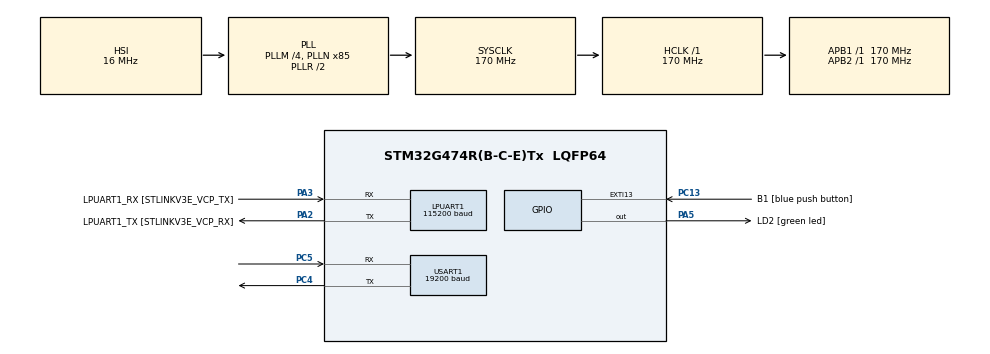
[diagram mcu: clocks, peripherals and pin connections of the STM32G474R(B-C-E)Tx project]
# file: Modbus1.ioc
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Dma.LPUART1_RX.2.Direction=DMA_PERIPH_TO_MEMORY
Dma.LPUART1_RX.2.EventEnable=DISABLE
Dma.LPUART1_RX.2.Instance=DMA1_Channel2
Dma.LPUART1_RX.2.MemDataAlignment=DMA_MDATAALIGN_BYTE
Dma.LPUART1_RX.2.MemInc=DMA_MINC_ENABLE
Dma.LPUART1_RX.2.Mode=DMA_NORMAL
Dma.LPUART1_RX.2.PeriphDataAlignment=DMA_PDATAALIGN_BYTE
Dma.LPUART1_RX.2.PeriphInc=DMA_PINC_DISABLE
Dma.LPUART1_RX.2.Polarity=HAL_DMAMUX_REQ_GEN_RISING
Dma.LPUART1_RX.2.Priority=DMA_PRIORITY_LOW
Dma.LPUART1_RX.2.RequestNumber=1
Dma.LPUART1_RX.2.SignalID=NONE
Dma.LPUART1_RX.2.SyncEnable=DISABLE
Dma.LPUART1_RX.2.SyncPolarity=HAL_DMAMUX_SYNC_NO_EVENT
Dma.LPUART1_RX.2.SyncRequestNumber=1
Dma.LPUART1_RX.2.SyncSignalID=NONE
Dma.LPUART1_TX.3.Direction=DMA_MEMORY_TO_PERIPH
Dma.LPUART1_TX.3.EventEnable=DISABLE
Dma.LPUART1_TX.3.Instance=DMA1_Channel1
Dma.LPUART1_TX.3.MemDataAlignment=DMA_MDATAALIGN_BYTE
Dma.LPUART1_TX.3.MemInc=DMA_MINC_ENABLE
Dma.LPUART1_TX.3.Mode=DMA_NORMAL
Dma.LPUART1_TX.3.PeriphDataAlignment=DMA_PDATAALIGN_BYTE
Dma.LPUART1_TX.3.PeriphInc=DMA_PINC_DISABLE
Dma.LPUART1_TX.3.Polarity=HAL_DMAMUX_REQ_GEN_RISING
Dma.LPUART1_TX.3.Priority=DMA_PRIORITY_LOW
Dma.LPUART1_TX.3.RequestNumber=1
Dma.LPUART1_TX.3.SignalID=NONE
Dma.LPUART1_TX.3.SyncEnable=DISABLE
Dma.LPUART1_TX.3.SyncPolarity=HAL_DMAMUX_SYNC_NO_EVENT
Dma.LPUART1_TX.3.SyncRequestNumber=1
Dma.LPUART1_TX.3.SyncSignalID=NONE
Dma.Request0=USART1_RX
Dma.Request1=USART1_TX
Dma.Request2=LPUART1_RX
Dma.Request3=LPUART1_TX
Dma.USART1_RX.0.Direction=DMA_PERIPH_TO_MEMORY
Dma.USART1_RX.0.EventEnable=DISABLE
Dma.USART1_RX.0.Instance=DMA1_Channel3
Dma.USART1_RX.0.MemDataAlignment=DMA_MDATAALIGN_BYTE
Dma.USART1_RX.0.MemInc=DMA_MINC_ENABLE
Dma.USART1_RX.0.Mode=DMA_NORMAL
Dma.USART1_RX.0.PeriphDataAlignment=DMA_PDATAALIGN_BYTE
Dma.USART1_RX.0.PeriphInc=DMA_PINC_DISABLE
Dma.USART1_RX.0.Polarity=HAL_DMAMUX_REQ_GEN_RISING
Dma.USART1_RX.0.Priority=DMA_PRIORITY_LOW
Dma.USART1_RX.0.RequestNumber=1
Dma.USART1_RX.0.SignalID=NONE
Dma.USART1_RX.0.SyncEnable=DISABLE
Dma.USART1_RX.0.SyncPolarity=HAL_DMAMUX_SYNC_NO_EVENT
Dma.USART1_RX.0.SyncRequestNumber=1
Dma.USART1_RX.0.SyncSignalID=NONE
Dma.USART1_TX.1.Direction=DMA_MEMORY_TO_PERIPH
Dma.USART1_TX.1.EventEnable=DISABLE
Dma.USART1_TX.1.Instance=DMA2_Channel1
Dma.USART1_TX.1.MemDataAlignment=DMA_MDATAALIGN_BYTE
Dma.USART1_TX.1.MemInc=DMA_MINC_ENABLE
Dma.USART1_TX.1.Mode=DMA_NORMAL
Dma.USART1_TX.1.PeriphDataAlignment=DMA_PDATAALIGN_BYTE
Dma.USART1_TX.1.PeriphInc=DMA_PINC_DISABLE
Dma.USART1_TX.1.Polarity=HAL_DMAMUX_REQ_GEN_RISING
Dma.USART1_TX.1.Priority=DMA_PRIORITY_LOW
Dma.USART1_TX.1.RequestNumber=1
Dma.USART1_TX.1.SignalID=NONE
Dma.USART1_TX.1.SyncEnable=DISABLE
Dma.USART1_TX.1.SyncPolarity=HAL_DMAMUX_SYNC_NO_EVENT
Dma.USART1_TX.1.SyncRequestNumber=1
Dma.USART1_TX.1.SyncSignalID=NONE
LPUART1.BaudRate=115200
LPUART1.Parity=UART_PARITY_EVEN
LPUART1.WordLength=UART_WORDLENGTH_9B
Mcu.Family=STM32G4
Mcu.Name=STM32G474R(B-C-E)Tx
Mcu.Package=LQFP64
NVIC.DMA1_Channel1_IRQn=true\:0\:0\:false\:false\:true\:false\:true\:true
NVIC.DMA1_Channel2_IRQn=true\:0\:0\:false\:false\:true\:false\:true\:true
NVIC.DMA1_Channel3_IRQn=true\:0\:0\:false\:false\:true\:false\:true\:true
NVIC.DMA2_Channel1_IRQn=true\:0\:0\:false\:false\:true\:false\:true\:true
NVIC.EXTI15_10_IRQn=true\:0\:0\:false\:false\:true\:true\:true\:true
NVIC.LPUART1_IRQn=true\:0\:0\:false\:false\:true\:true\:true\:true
NVIC.PriorityGroup=NVIC_PRIORITYGROUP_4
NVIC.TIM1_UP_TIM16_IRQn=true\:0\:0\:false\:false\:true\:true\:true\:true
NVIC.USART1_IRQn=true\:0\:0\:false\:false\:true\:true\:true\:true
PA13.GPIO_Label=T_SWDIO
PA13.Mode=Serial_Wire
PA13.Signal=SYS_JTMS-SWDIO
PA14.GPIO_Label=T_SWCLK
PA14.Mode=Serial_Wire
PA14.Signal=SYS_JTCK-SWCLK
PA2.GPIO_Label=LPUART1_TX [STLINKV3E_VCP_RX]
PA2.Mode=Asynchronous
PA2.Signal=LPUART1_TX
PA3.GPIO_Label=LPUART1_RX [STLINKV3E_VCP_TX]
PA3.Mode=Asynchronous
PA3.Signal=LPUART1_RX
PA5.GPIO_Label=LD2 [green led]
PA5.Signal=GPIO_Output
PB3.GPIO_Label=T_SWO
PB3.Signal=SYS_JTDO-SWO
PC13.GPIO_Label=B1 [blue push button]
PC13.Signal=GPXTI13
PC14-OSC32_IN.Mode=LSE-External-Oscillator
PC14-OSC32_IN.Signal=RCC_OSC32_IN
PC15-OSC32_OUT.Mode=LSE-External-Oscillator
PC15-OSC32_OUT.Signal=RCC_OSC32_OUT
PC4.Mode=Asynchronous
PC4.Signal=USART1_TX
PC5.Mode=Asynchronous
PC5.Signal=USART1_RX
PF0-OSC_IN.Mode=HSE-External-Oscillator
PF0-OSC_IN.Signal=RCC_OSC_IN
PF1-OSC_OUT.Mode=HSE-External-Oscillator
PF1-OSC_OUT.Signal=RCC_OSC_OUT
ProjectManager.HeapSize=0x200
ProjectManager.StackSize=0x400
ProjectManager.TargetToolchain=STM32CubeIDE
RCC.ADC12Freq_Value=170000000
RCC.ADC345Freq_Value=170000000
RCC.AHBFreq_Value=170000000
RCC.APB1Freq_Value=170000000
RCC.APB1TimFreq_Value=170000000
RCC.APB2Freq_Value=170000000
RCC.APB2TimFreq_Value=170000000
RCC.CortexFreq_Value=170000000
RCC.EXTERNAL_CLOCK_VALUE=12288000
RCC.HCLKFreq_Value=170000000
RCC.HSE_VALUE=24000000
RCC.HSI48_VALUE=48000000
RCC.HSI_VALUE=16000000
RCC.PLLM=RCC_PLLM_DIV4
RCC.PLLN=85
RCC.RTCClockSelection=RCC_RTCCLKSOURCE_LSE
RCC.SYSCLKFreq_VALUE=170000000
RCC.SYSCLKSource=RCC_SYSCLKSOURCE_PLLCLK
RCC.USBFreq_Value=170000000
RCC.VCOOutputFreq_Value=340000000
TIM16.PeriodNoDither=1145
TIM16.Prescaler=169
USART1.BaudRate=19200
USART1.Parity=PARITY_EVEN
USART1.VirtualMode-Asynchronous=VM_ASYNC
USART1.WordLength=WORDLENGTH_9B
VP_SYS_VS_DBSignals.Mode=DisableDeadBatterySignals
VP_TIM16_VS_ClockSourceINT.Mode=Enable_Timer
VP_TIM16_VS_OPM.Mode=OPM_bit
board=NUCLEO-G474RE

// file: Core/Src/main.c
/* USER CODE BEGIN Header */
/**
  ******************************************************************************
  * @file           : main.c
  * @brief          : Main program body
  ******************************************************************************
  * @attention
  *
  * Copyright (c) 2024 STMicroelectronics.
  * All rights reserved.
  *
  * This software is licensed under terms that can be found in the LICENSE file
  * in the root directory of this software component.
  * If no LICENSE file comes with this software, it is provided AS-IS.
  *
  ******************************************************************************
  */
/* USER CODE END Header */
#include "main.h"

/* USER CODE BEGIN Includes */
#include "ModBusRTU.h"
/* USER CODE END Includes */

UART_HandleTypeDef hlpuart1;
UART_HandleTypeDef huart1;
DMA_HandleTypeDef hdma_lpuart1_rx;
DMA_HandleTypeDef hdma_lpuart1_tx;
DMA_HandleTypeDef hdma_usart1_rx;
DMA_HandleTypeDef hdma_usart1_tx;

TIM_HandleTypeDef htim16;

/* USER CODE BEGIN PV */
ModbusHandleTypedef hmodbus;
u16u8_t registerFrame[200];
/* USER CODE END PV */

void SystemClock_Config(void);
static void MX_GPIO_Init(void);
static void MX_DMA_Init(void);
static void MX_LPUART1_UART_Init(void);
static void MX_USART1_UART_Init(void);
static void MX_TIM16_Init(void);

int main(void)
{

  /* MCU Configuration--------------------------------------------------------*/

  /* Reset of all peripherals, Initializes the Flash interface and the Systick. */
  HAL_Init();

  /* Configure the system clock */
  SystemClock_Config();

  /* Initialize all configured peripherals */
  MX_GPIO_Init();
  MX_DMA_Init();
  MX_LPUART1_UART_Init();
  MX_USART1_UART_Init();
  MX_TIM16_Init();
  /* USER CODE BEGIN 2 */
  hmodbus.huart = &hlpuart1;
  hmodbus.htim = &htim16;
  hmodbus.slaveAddress = 0x15;
  hmodbus.RegisterSize =200;
  Modbus_init(&hmodbus, registerFrame);
  /* USER CODE END 2 */

  /* Infinite loop */
  while (1)
  {

    /* USER CODE BEGIN 3 */
	  Modbus_Protocal_Worker();
  }
  /* USER CODE END 3 */
}

void SystemClock_Config(void)
{
  RCC_OscInitTypeDef RCC_OscInitStruct = {0};
  RCC_ClkInitTypeDef RCC_ClkInitStruct = {0};

  /** Configure the main internal regulator output voltage
  */
  HAL_PWREx_ControlVoltageScaling(PWR_REGULATOR_VOLTAGE_SCALE1_BOOST);

  /** Initializes the RCC Oscillators according to the specified parameters
  * in the RCC_OscInitTypeDef structure.
  */
  RCC_OscInitStruct.OscillatorType = RCC_OSCILLATORTYPE_HSI;
  RCC_OscInitStruct.HSIState = RCC_HSI_ON;
  RCC_OscInitStruct.HSICalibrationValue = RCC_HSICALIBRATION_DEFAULT;
  RCC_OscInitStruct.PLL.PLLState = RCC_PLL_ON;
  RCC_OscInitStruct.PLL.PLLSource = RCC_PLLSOURCE_HSI;
  RCC_OscInitStruct.PLL.PLLM = RCC_PLLM_DIV4;
  RCC_OscInitStruct.PLL.PLLN = 85;
  RCC_OscInitStruct.PLL.PLLP = RCC_PLLP_DIV2;
  RCC_OscInitStruct.PLL.PLLQ = RCC_PLLQ_DIV2;
  RCC_OscInitStruct.PLL.PLLR = RCC_PLLR_DIV2;
  if (HAL_RCC_OscConfig(&RCC_OscInitStruct) != HAL_OK)
  {
    Error_Handler();
  }

  /** Initializes the CPU, AHB and APB buses clocks
  */
  RCC_ClkInitStruct.ClockType = RCC_CLOCKTYPE_HCLK|RCC_CLOCKTYPE_SYSCLK
                              |RCC_CLOCKTYPE_PCLK1|RCC_CLOCKTYPE_PCLK2;
  RCC_ClkInitStruct.SYSCLKSource = RCC_SYSCLKSOURCE_PLLCLK;
  RCC_ClkInitStruct.AHBCLKDivider = RCC_SYSCLK_DIV1;
  RCC_ClkInitStruct.APB1CLKDivider = RCC_HCLK_DIV1;
  RCC_ClkInitStruct.APB2CLKDivider = RCC_HCLK_DIV1;

  if (HAL_RCC_ClockConfig(&RCC_ClkInitStruct, FLASH_LATENCY_4) != HAL_OK)
  {
    Error_Handler();
  }
}

static void MX_LPUART1_UART_Init(void)
{

  hlpuart1.Instance = LPUART1;
  hlpuart1.Init.BaudRate = 115200;
  hlpuart1.Init.WordLength = UART_WORDLENGTH_9B;
  hlpuart1.Init.StopBits = UART_STOPBITS_1;
  hlpuart1.Init.Parity = UART_PARITY_EVEN;
  hlpuart1.Init.Mode = UART_MODE_TX_RX;
  hlpuart1.Init.HwFlowCtl = UART_HWCONTROL_NONE;
  hlpuart1.Init.OneBitSampling = UART_ONE_BIT_SAMPLE_DISABLE;
  hlpuart1.Init.ClockPrescaler = UART_PRESCALER_DIV1;
  hlpuart1.AdvancedInit.AdvFeatureInit = UART_ADVFEATURE_NO_INIT;
  if (HAL_UART_Init(&hlpuart1) != HAL_OK)
  {
    Error_Handler();
  }
  if (HAL_UARTEx_SetTxFifoThreshold(&hlpuart1, UART_TXFIFO_THRESHOLD_1_8) != HAL_OK)
  {
    Error_Handler();
  }
  if (HAL_UARTEx_SetRxFifoThreshold(&hlpuart1, UART_RXFIFO_THRESHOLD_1_8) != HAL_OK)
  {
    Error_Handler();
  }
  if (HAL_UARTEx_DisableFifoMode(&hlpuart1) != HAL_OK)
  {
    Error_Handler();
  }

}

static void MX_USART1_UART_Init(void)
{

  huart1.Instance = USART1;
  huart1.Init.BaudRate = 19200;
  huart1.Init.WordLength = UART_WORDLENGTH_9B;
  huart1.Init.StopBits = UART_STOPBITS_1;
  huart1.Init.Parity = UART_PARITY_EVEN;
  huart1.Init.Mode = UART_MODE_TX_RX;
  huart1.Init.HwFlowCtl = UART_HWCONTROL_NONE;
  huart1.Init.OverSampling = UART_OVERSAMPLING_16;
  huart1.Init.OneBitSampling = UART_ONE_BIT_SAMPLE_DISABLE;
  huart1.Init.ClockPrescaler = UART_PRESCALER_DIV1;
  huart1.AdvancedInit.AdvFeatureInit = UART_ADVFEATURE_NO_INIT;
  if (HAL_UART_Init(&huart1) != HAL_OK)
  {
    Error_Handler();
  }
  if (HAL_UARTEx_SetTxFifoThreshold(&huart1, UART_TXFIFO_THRESHOLD_1_8) != HAL_OK)
  {
    Error_Handler();
  }
  if (HAL_UARTEx_SetRxFifoThreshold(&huart1, UART_RXFIFO_THRESHOLD_1_8) != HAL_OK)
  {
    Error_Handler();
  }
  if (HAL_UARTEx_DisableFifoMode(&huart1) != HAL_OK)
  {
    Error_Handler();
  }

}

static void MX_TIM16_Init(void)
{

  htim16.Instance = TIM16;
  htim16.Init.Prescaler = 169;
  htim16.Init.CounterMode = TIM_COUNTERMODE_UP;
  htim16.Init.Period = 1145;
  htim16.Init.ClockDivision = TIM_CLOCKDIVISION_DIV1;
  htim16.Init.RepetitionCounter = 0;
  htim16.Init.AutoReloadPreload = TIM_AUTORELOAD_PRELOAD_DISABLE;
  if (HAL_TIM_Base_Init(&htim16) != HAL_OK)
  {
    Error_Handler();
  }
  if (HAL_TIM_OnePulse_Init(&htim16, TIM_OPMODE_SINGLE) != HAL_OK)
  {
    Error_Handler();
  }

}

static void MX_DMA_Init(void)
{

  /* DMA controller clock enable */
  __HAL_RCC_DMAMUX1_CLK_ENABLE();
  __HAL_RCC_DMA1_CLK_ENABLE();
  __HAL_RCC_DMA2_CLK_ENABLE();

  /* DMA interrupt init */
  /* DMA1_Channel1_IRQn interrupt configuration */
  HAL_NVIC_SetPriority(DMA1_Channel1_IRQn, 0, 0);
  HAL_NVIC_EnableIRQ(DMA1_Channel1_IRQn);
  /* DMA1_Channel2_IRQn interrupt configuration */
  HAL_NVIC_SetPriority(DMA1_Channel2_IRQn, 0, 0);
  HAL_NVIC_EnableIRQ(DMA1_Channel2_IRQn);
  /* DMA1_Channel3_IRQn interrupt configuration */
  HAL_NVIC_SetPriority(DMA1_Channel3_IRQn, 0, 0);
  HAL_NVIC_EnableIRQ(DMA1_Channel3_IRQn);
  /* DMA2_Channel1_IRQn interrupt configuration */
  HAL_NVIC_SetPriority(DMA2_Channel1_IRQn, 0, 0);
  HAL_NVIC_EnableIRQ(DMA2_Channel1_IRQn);

}

static void MX_GPIO_Init(void)
{
  GPIO_InitTypeDef GPIO_InitStruct = {0};

  /* GPIO Ports Clock Enable */
  __HAL_RCC_GPIOC_CLK_ENABLE();
  __HAL_RCC_GPIOF_CLK_ENABLE();
  __HAL_RCC_GPIOA_CLK_ENABLE();
  __HAL_RCC_GPIOB_CLK_ENABLE();

  /*Configure GPIO pin Output Level */
  HAL_GPIO_WritePin(LD2_GPIO_Port, LD2_Pin, GPIO_PIN_RESET);

  /*Configure GPIO pin : B1_Pin */
  GPIO_InitStruct.Pin = B1_Pin;
  GPIO_InitStruct.Mode = GPIO_MODE_IT_RISING;
  GPIO_InitStruct.Pull = GPIO_NOPULL;
  HAL_GPIO_Init(B1_GPIO_Port, &GPIO_InitStruct);

  /*Configure GPIO pin : LD2_Pin */
  GPIO_InitStruct.Pin = LD2_Pin;
  GPIO_InitStruct.Mode = GPIO_MODE_OUTPUT_PP;
  GPIO_InitStruct.Pull = GPIO_NOPULL;
  GPIO_InitStruct.Speed = GPIO_SPEED_FREQ_LOW;
  HAL_GPIO_Init(LD2_GPIO_Port, &GPIO_InitStruct);

  /* EXTI interrupt init*/
  HAL_NVIC_SetPriority(EXTI15_10_IRQn, 0, 0);
  HAL_NVIC_EnableIRQ(EXTI15_10_IRQn);

}

void Error_Handler(void)
{
  __disable_irq();
  while (1)
  {
  }
}
